# GD32M53x register map
File version: 1.0
CPU: CM33 r2p1, little endian, MPU, FPU, DSP, 4 interrupt priority bits
Registers are 32-bit, read-write, reset 0x0 unless marked. A register's access mark holds for its fields unless they carry their own. Offsets are from the block's base; [hi:lo] are bit positions; lines under a group give offsets from that group; {n}, {i} and the like mark numbered series; 'fields as' and 'values as' point back to an identical list.

## ADC0 — Analog-to-digital converter
Base 0x40012000
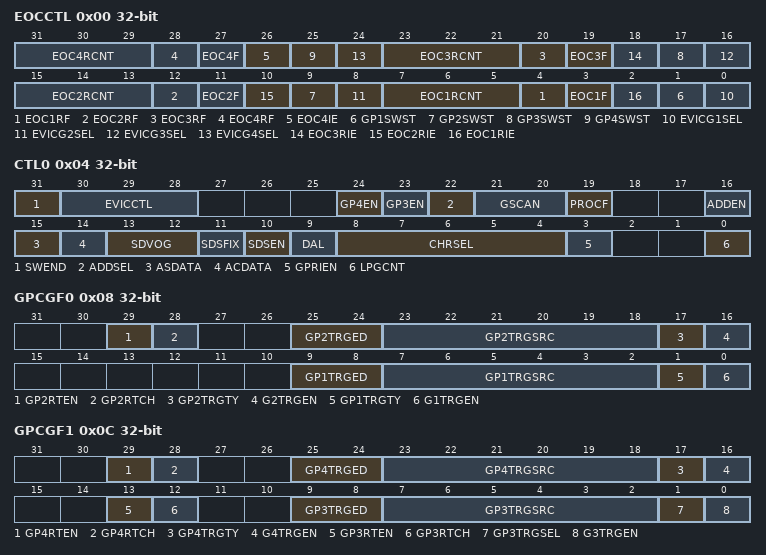
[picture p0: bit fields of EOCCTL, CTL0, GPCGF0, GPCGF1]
0x00 EOCCTL — Software EOC control register
  [8n-1:8n-3] EOC{n}RCNT (n=1..4) — End of Group_pri{n} conversion round counts
  [8n-4] EOC{n}RF (n=1..4) — End of Group_pri{n} conversion round flag
  [8n-5] EOC{n}F (n=1..4) — End of Group_pri{n} conversion flag
  [26] EOC4IE — Software interrupt generated by end of Group_pri4 conversion round control enable
  [8n-7] GP{n}SWST (n=1..4) — Software start flag of Group_pri{n}
  [8n-8] EVICG{n}SEL (n=1..4) — EVIC trigger signal select from Group_pri{n}
  [18] EOC3RIE — Interrupt enable for EOC3RF
  [10] EOC2RIE — Interrupt enable for EOC2RF
  [2] EOC1RIE — Interrupt enable for EOC1RF
0x04 CTL0 access per field — Control register 0
  [31] SWEND rw — Software start end of Group_pri1/pri2/pri3
  [30:28] EVICCTL rw — EVIC Link signal control
  [24] GP4EN rw — Enables A/D conversion operation for Group_pri4
  [23] GP3EN rw — Enables A/D conversion operation for Group_pri4
  [22] ADDSEL rw — A/D conversion data addition mode selection
  [21:20] GSCAN rw — Group scan mode
  [19] PROCF ro — A/D conversion process flag
  [16] ADDEN rw — Addition function enable
  [15] ASDATA rw — Enable automatic setting data registers
  [14] ACDATA rw — Enable automatic clearing data registers
  [13:12] SDVOG rw — Configure fix voltage for self-diagnosis conversion
  [11] SDSFIX rw — Enable fix mode for self-diagnosis voltage
  [10] SDSEN rw — Enable self-diagnosis
  [9] DAL rw — Data storage alignment mode
  [8:4] CHRSEL rw — Select precharge and discharge
  [3] GPRIEN rw — Enable group priority
  [0] LPGCNT rw — Enable lowest-priority group scan continuous
0x08 GPCGF0 — Group config register 0
  [29] GP2RTEN — Group_pri2 Restart Setting
  [28] GP2RTCH — Group_pri2 Restart Channel Select
  [25:24] GP2TRGED — Trigger edge select of Group_pri2
  [23:18] GP2TRGSRC — Synchronous trigger source for Group_pri2
  [17] GP2TRGTY — Group_pri2 trigger type select
  [16] G2TRGEN — Enable Group_pri2 synchronous or asynchronous trigger
  [9:8] GP1TRGED — Trigger edge select of Group_pri1
  [7:2] GP1TRGSRC — Synchronous trigger source for Group_pri1
  [1] GP1TRGTY — Group_pri1 trigger type select
  [0] G1TRGEN — Enable Group_pri1 synchronous or asynchronous trigger
0x0C GPCGF1 — Group config register 1
  [29] GP4RTEN — Group_pri4 Restart Setting
  [28] GP4RTCH — Group_pri4 Restart Channel Select
  [25:24] GP4TRGED — Trigger edge select of Group_pri4
  [23:18] GP4TRGSRC — Synchronous trigger source for Group_pri4
  [17] GP4TRGTY — Group_pri4 trigger type select
  [16] G4TRGEN — Enable Group_pri4 synchronous or asynchronous trigger
  [13] GP3RTEN — Group_pri3 Restart Setting
  [12] GP3RTCH — Group_pri3 Restart Channel Select
  [9:8] GP3TRGED — Trigger edge select of Group_pri3
  [7:2] GP3TRGSRC — Synchronous trigger source for Group_pri3
  [1] GP3TRGSEL — Group_pri3 trigger type select
  [0] G3TRGEN — Enable Group_pri3 synchronous or asynchronous trigger
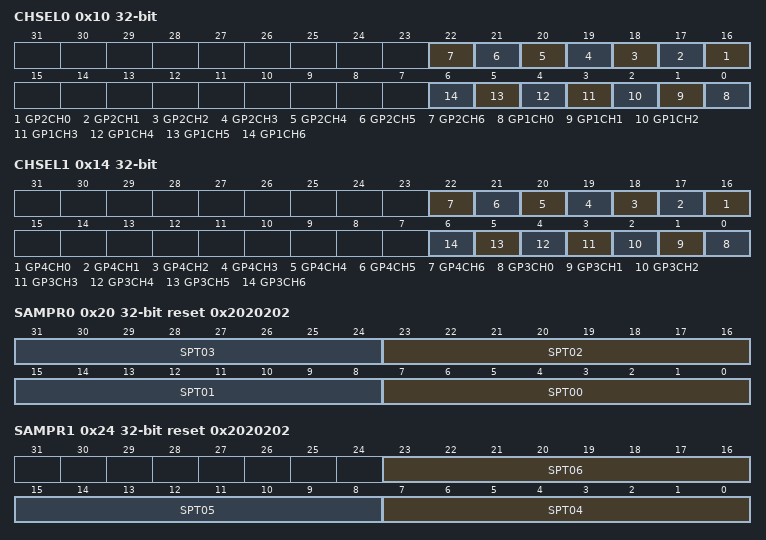
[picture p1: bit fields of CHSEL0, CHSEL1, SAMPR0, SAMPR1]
0x10 CHSEL0 — Channel selection register 0
  [n+16] GP2CH{n} (n=0..6) — Select channel ADCx_IN{n:02} in Group_pri2
  [n] GP1CH{n} (n=0..6) — Select channel ADCx_IN{n:02} in Group_pri1
0x14 CHSEL1 — Channel selection register 1
  [n+16] GP4CH{n} (n=0..6) — Select channel ADCx_IN{n:02} in Group_pri4
  [n] GP3CH{n} (n=0..6) — Select channel ADCx_IN{n:02} in Group_pri3
0x20 SAMPR0 reset 0x2020202 — Sample time register 0
  [8n+7:8n] SPT{n:02} (n=0..3) — Channel ADCx_IN{n:02} sampling time
0x24 SAMPR1 reset 0x2020202 — Sample time register 1
  [23:16] SPT06 — Channel ADCx_IN06 sampling time
  [15:8] SPT05 — Channel ADCx_IN05 sampling time
  [7:0] SPT04 — Channel ADCx_IN04 sampling time
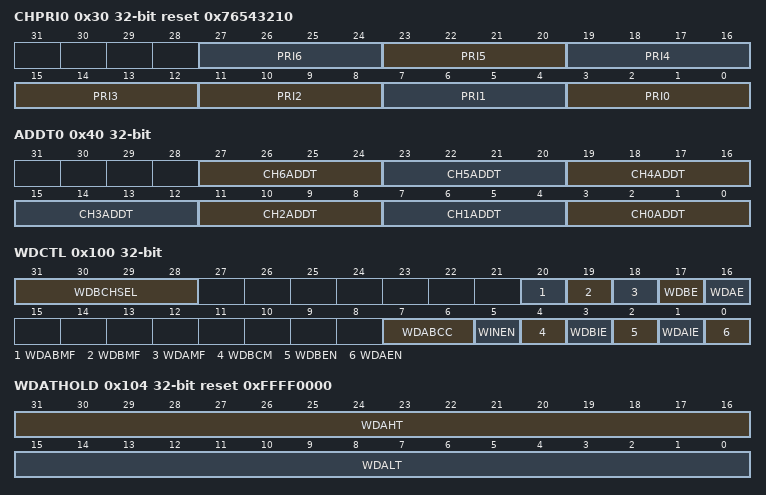
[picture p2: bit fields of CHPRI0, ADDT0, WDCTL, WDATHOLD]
0x30 CHPRI0 reset 0x76543210 — Channel priority register 0
  [4n+3:4n] PRI{n} (n=3..6) — The {n}th priority of the selected channel
  [11:8] PRI2 — The 2nd priority of the selected channel
  [7:4] PRI1 — The 1st priority of the selected channel
  [3:0] PRI0 — The zeroth priority of the selected channel
0x40 ADDT0 — ADC channel addition times register 0
  [4n+3:4n] CH{n}ADDT (n=0..6) — The total addition conversion times of ADCx_IN{n:02}
0x50 SDDATA ro — Self-diagnosis data register
  [15:0] SDDATA — The self-diagnosis data
{0x54+0xC*i} GP{i}BIDATA ro (i=1..4) — Group_prix bifurcate data register
  [15:0] BIDATA — The data by the second trigger in bifurcate trigger mode
0x64 GP1BIDATA1 ro — Group_prix bifurcate data register 1
  fields as GP1BIDATA
0x68 GP1BIDATA2 ro — Group_prix bifurcate data register 2
  [15:0] BIDATA1 — The data by the first trigger in bifurcate trigger mode
{0x58+0xC*i} GP{i}BIDATA1 ro (i=2..4) — Group_prix bifurcate data register 1
  fields as GP1BIDATA2
0x74 GP2BIDATA2 ro — Group_prix bifurcate data register 2
  fields as GP1BIDATA2
0x80 GP3BIDATA2 ro — Group_prix bifurcate data register 2
  [15:0] BIDATA2 — The data by the second trigger in bifurcate trigger mode
0x8C GP4BIDATA2 ro — Group_prix bifurcate data register 2
  fields as GP3BIDATA2
{0x8C+4i} GP{i}DMAR ro (i=1..3) — Group_prix data DMA register
  fields as GP3BIDATA2
0x9C GP4DMAR ro — Group_prix data DMA register
  [15:0] DATA — The data of Group_prix which can be accessed by DMA
{0xA0+4i} CH{i}DATA ro (i=0..6) — Channel {i} data register
  [15:0] CHxDATA — Channel 15 data
0x100 WDCTL access per field — Watchdog control register
  [31:28] WDBCHSEL rw — Analog watchdog B channel select
  [20] WDABMF ro — Analog watchdog A/B complex compare monitor flag
  [19] WDBMF ro — Analog watchdog B compare monitor flag
  [18] WDAMF ro — Analog watchdog A compare monitor flag
  [17] WDBE rw — Analog watchdog B event flag
  [16] WDAE rw — Analog watchdog A event flag
  [7:6] WDABCC rw — Watchdog A/B complex conditions configuration
  [5] WINEN rw — Window mode enable
  [4] WDBCM rw — Watchdog B compare mode
  [3] WDBIE rw — Interrupt enable for watchdog B
  [2] WDBEN rw — Watchdog B enable
  [1] WDAIE rw — Interrupt enable for watchdog A
  [0] WDAEN rw — Watchdog A enable
0x104 WDATHOLD reset 0xFFFF0000 — Watchdog A threshold register
  [31:16] WDAHT — High threshold for analog watchdog A
  [15:0] WDALT — Low threshold for analog watchdog A
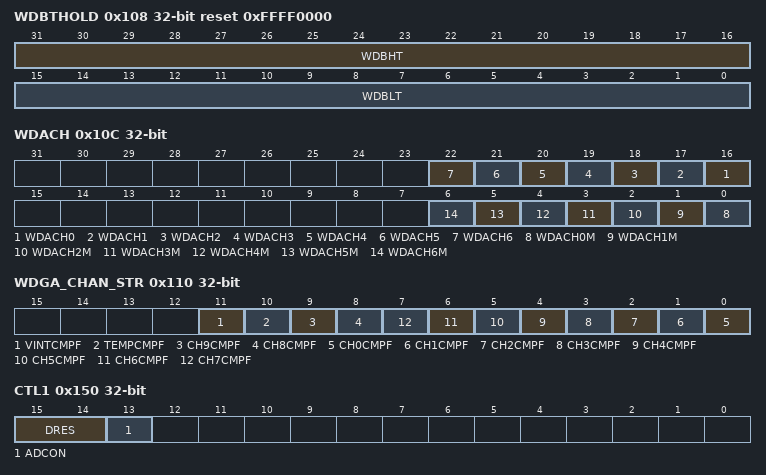
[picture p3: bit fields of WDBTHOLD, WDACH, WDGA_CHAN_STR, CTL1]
0x108 WDBTHOLD reset 0xFFFF0000 — Watchdog B threshold register
  [31:16] WDBHT — High threshold for analog watchdog B
  [15:0] WDBLT — Low threshold for analog watchdog B
0x10C WDACH — Watchdog A channel config register
  [n+16] WDACH{n} (n=0..6) — Select ADCx_IN{n} for watchdog A
  [n] WDACH{n}M (n=0..6) — Channel ADCx_IN{n:02} watchdog A compare mode
0x110 WDGA_CHAN_STR — Window A compare channel status register, ADC_WDGA_CHAN_STR
  [11] VINTCMPF — Internal reference voltage channel Window A compare status
  [10] TEMPCMPF — Temperature sensor channel Window A compare status
  [9] CH9CMPF — Channel ADCx_IN09 Window A compare status
  [8] CH8CMPF — Channel ADCX_IN08 Window A compare status
  [n] CH{n}CMPF (n=0..7) — Channel ADCx_IN{n:02} Window A compare status
0x150 CTL1 — Control register 1
  [15:14] DRES — ADC resolution
  [13] ADCON
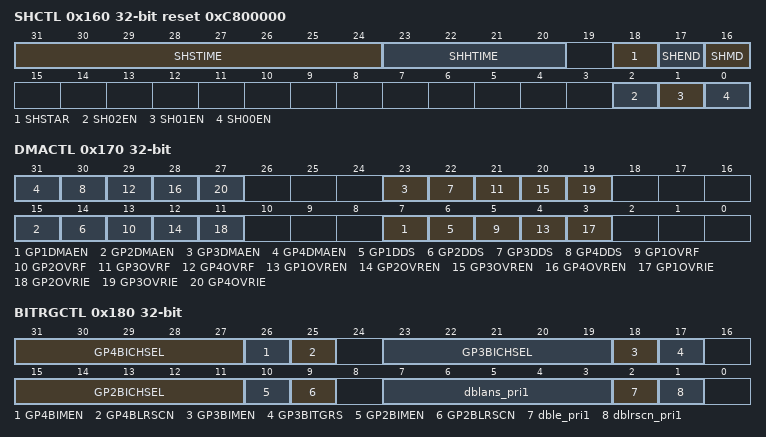
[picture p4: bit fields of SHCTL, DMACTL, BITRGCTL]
0x160 SHCTL reset 0xC800000 — Sample-and-hold control register
  [31:24] SHSTIME — The sample time of sample-and-hold circuit
  [23:20] SHHTIME — The hold time of sample-and-hold circuit
  [18] SHSTAR — Software start flag of sample-and-hold circuit in Constant sampling mod
  [17] SHEND — Software end flag of sample-and-hold circuit in Constant sampling mod
  [16] SHMD — Channel-Dedicated Sample-and-Hold Circuit Operating Mode Setting
  [2] SH02EN — Enable channel ADCx_IN02 sample-and-hold circuit
  [1] SH01EN — Enable channel ADCx_IN01 sample-and-hold circuit
  [0] SH00EN — Enable channel ADCx_IN00 sample-and-hold circuit
0x170 DMACTL — DMA control register
  [8n-1] GP{n}DMAEN (n=1..4) — DMA request enable of Group_pri{n}
  [8n-2] GP{n}DDS (n=1..4) — DMA disable mode of Group_pri{n}
  [8n-3] GP{n}OVRF (n=1..4) — DMA overrun flag of Group_pri{n}
  [8n-4] GP{n}OVREN (n=1..4) — DMA overrun detect enable of Group_pri{n}
  [8n-5] GP{n}OVRIE (n=1..4) — DMA overrun detect interrupt enable of Group_pri{n}
0x180 BITRGCTL — Bifurcate trigger control register
  [31:27] GP4BICHSEL — Bifurcate Trigger Channel Select of Group_pri4
  [26] GP4BIMEN — Bifurcate Trigger Mode enable of Group_pri4
  [25] GP4BLRSCN — For any group use double trigger function, the next trigger during the current A/D conversion round restore enable:
  [23:19] GP3BICHSEL — Bifurcate Trigger Channel Select of Group_pri4
  [18] GP3BIMEN — Bifurcate Trigger Mode enable of Group_pri4
  [17] GP3BITGRS — Enable the next trigger restore of Group_pri3
  [15:11] GP2BICHSEL — Bifurcate Trigger Channel Select of Group_pri4
  [10] GP2BIMEN — Bifurcate Trigger Mode enable of Group_pri4
  [9] GP2BLRSCN — For any group use double trigger function, the next trigger during the current A/D conversion round restore enable:
  [7:3] dblans_pri1 — Bifurcate Trigger Channel Select of Group_pri1
  [2] dble_pri1 — Bifurcate Trigger Mode enable of Group_pri1
  [1] dblrscn_pri1 — For any group use double trigger function, the next trigger during the current A/D conversion round restore enable:

## ADC2 — Analog to digital converter
Base 0x40012400
Registers as ADC0, without SHCTL; these are added or differ:
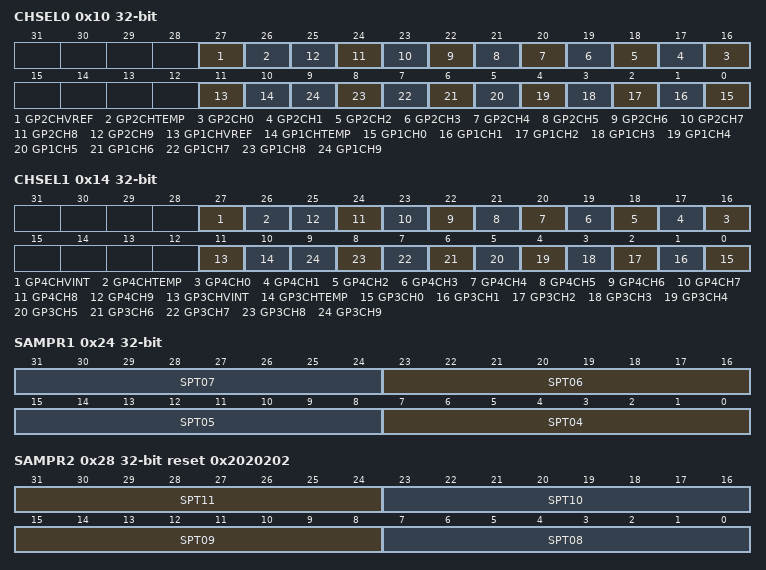
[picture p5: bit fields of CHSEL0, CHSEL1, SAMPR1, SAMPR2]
0x10 CHSEL0 — Channel selection register 0
  [27] GP2CHVREF — Select Internal Reference Voltage A/D Conversion in Group_pri2
  [26] GP2CHTEMP — Select Temperature Sensor A/D Conversion in Group_pri2
  [n+16] GP2CH{n} (n=0..9) — Select channel ADCx_IN{n:02} in Group_pri2
  [11] GP1CHVREF — Select Internal Reference Voltage A/D Conversion in Group_pri1
  [10] GP1CHTEMP — Select Temperature Sensor A/D Conversion in Group_pri1
  [n] GP1CH{n} (n=0..9) — Select channel ADCx_IN{n:02} in Group_pri1
0x14 CHSEL1 — Channel selection register 1
  [27] GP4CHVINT — Select Internal Reference Voltage A/D Conversion in Group_pri4
  [26] GP4CHTEMP — Select Temperature Sensor A/D Conversion in Group_pri4
  [n+16] GP4CH{n} (n=0..9) — Select channel ADCx_IN{n:02} in Group_pri4
  [11] GP3CHVINT — Select Internal Reference Voltage A/D Conversion in Group_pri3
  [10] GP3CHTEMP — Select Temperature Sensor A/D Conversion in Group_pri3
  [n] GP3CH{n} (n=0..9) — Select channel ADCx_IN{n:02} in Group_pri3
0x24 SAMPR1 — Sample time register 1
  [8n-25:8n-32] SPT{n:02} (n=4..7) — Channel ADCx_IN{n:02} sampling time
0x28 SAMPR2 reset 0x2020202 — Sample time register 2
  [31:24] SPT11 — Internal voltage channel sampling time
  [23:16] SPT10 — Temperature sensor channel sampling time
  [15:8] SPT09 — Channel ADCx_IN09 sampling time
  [7:0] SPT08 — Channel ADCx_IN08 sampling time
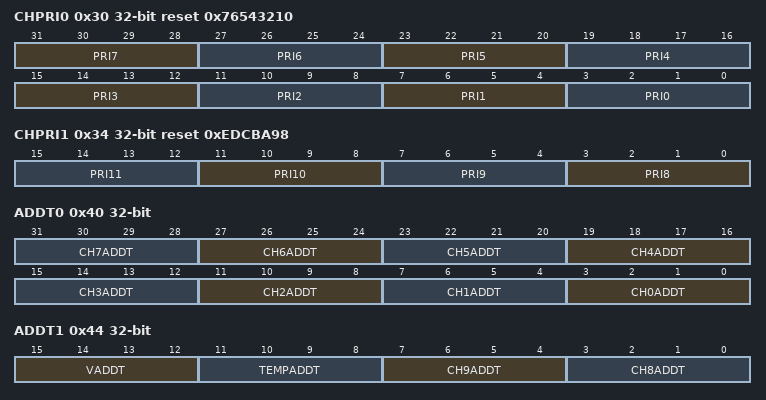
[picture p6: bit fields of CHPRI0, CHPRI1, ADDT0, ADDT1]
0x30 CHPRI0 reset 0x76543210 — Channel priority register 0
  [4n+3:4n] PRI{n} (n=3..7) — The {n}th priority of the selected channel
  [11:8] PRI2 — The 2nd priority of the selected channel
  [7:4] PRI1 — The 1st priority of the selected channel
  [3:0] PRI0 — The zeroth priority of the selected channel
0x34 CHPRI1 reset 0xEDCBA98 — Channel priority register 1
  [4n-29:4n-32] PRI{n} (n=8..11) — The {n}th priority of the selected channel
0x40 ADDT0 — ADC channel addition times register 0
  [4n+3:4n] CH{n}ADDT (n=0..7) — The total addition conversion times of ADCx_IN{n:02}
0x44 ADDT1 — ADC channel addition times register 1
  [15:12] VADDT — The total addition conversion times of internal reference voltage channel
  [11:8] TEMPADDT — The total addition conversion times of temperature sensor channel
  [7:4] CH9ADDT — The total addition conversion times of ADCx_IN09
  [3:0] CH8ADDT — The total addition conversion times of ADCx_IN08
{0xA0+4i} CH{i}DATA ro (i=7..9) — Channel {i} data register
  [15:0] CHxDATA — Channel 15 data
0xC8 TEMPDATA ro — Temperature sensor data register
  [16:0] TEMPDATA — Temperature sensor data
0xCC VINTDATA ro — Internal reference voltage data register
  [15:0] VINTDATA — Internal reference voltage channel data
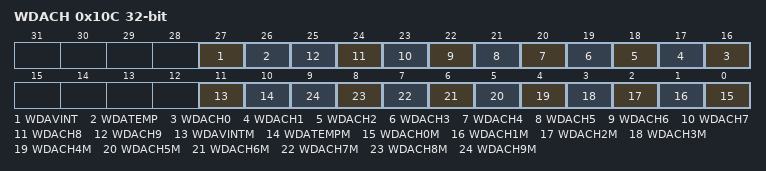
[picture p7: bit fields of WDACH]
0x10C WDACH — Watchdog A channel config register
  [27] WDAVINT — Select internal reference voltage channel for watchdog A
  [26] WDATEMP — Select temperature sensor channel for watchdog A
  [n+16] WDACH{n} (n=0..9) — Select ADCx_IN{n} for watchdog A
  [11] WDAVINTM — Internal reference voltage channel watchdog A compare mode
  [10] WDATEMPM — Temperature sensor channel watchdog A compare mode
  [n] WDACH{n}M (n=0..9) — Channel ADCx_IN{n:02} watchdog A compare mode
